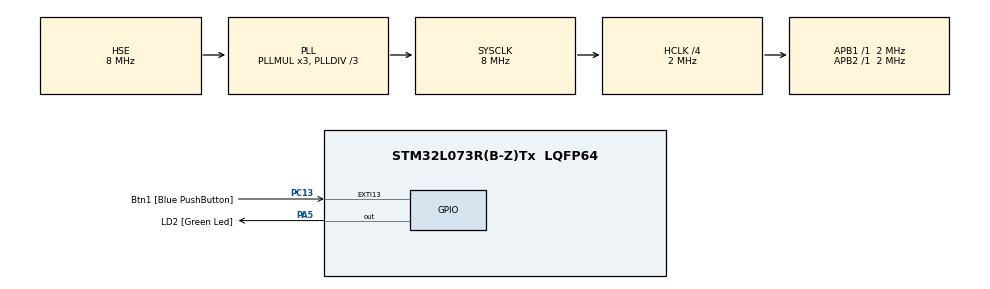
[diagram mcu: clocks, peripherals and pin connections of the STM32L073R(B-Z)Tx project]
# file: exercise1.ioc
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Mcu.Family=STM32L0
Mcu.Name=STM32L073R(B-Z)Tx
Mcu.Package=LQFP64
NVIC.EXTI4_15_IRQn=true\:0\:0\:false\:false\:true\:true
PA13.Mode=Serial_Wire
PA13.Signal=SYS_SWDIO
PA14.Mode=Serial_Wire
PA14.Signal=SYS_SWCLK
PA5.GPIO_Label=LD2 [Green Led]
PA5.Signal=GPIO_Output
PC13.GPIO_Label=Btn1 [Blue PushButton]
PC13.Signal=GPXTI13
PH0-OSC_IN.Mode=HSE-External-Oscillator
PH0-OSC_IN.Signal=RCC_OSC_IN
PH1-OSC_OUT.Mode=HSE-External-Oscillator
PH1-OSC_OUT.Signal=RCC_OSC_OUT
ProjectManager.HeapSize=0x200
ProjectManager.StackSize=0x400
ProjectManager.TargetToolchain=MDK-ARM V5
RCC.AHBCLKDivider=RCC_SYSCLK_DIV4
RCC.AHBFreq_Value=2000000
RCC.APB1Freq_Value=2000000
RCC.APB1TimFreq_Value=2000000
RCC.APB2Freq_Value=2000000
RCC.APB2TimFreq_Value=2000000
RCC.HCLKFreq_Value=2000000
RCC.HSI16_VALUE=16000000
RCC.HSI48_VALUE=48000000
RCC.HSI_VALUE=16000000
RCC.MSI_VALUE=2097000
RCC.PLLDIV=RCC_PLLDIV_3
RCC.PLLSourceVirtual=RCC_PLLSOURCE_HSE
RCC.SYSCLKFreq_VALUE=8000000
RCC.SYSCLKSource=RCC_SYSCLKSOURCE_PLLCLK
RCC.VCOOutputFreq_Value=24000000
board=NUCLEO-L073RZ

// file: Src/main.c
/**
  ******************************************************************************
  * @file           : main.c
  * @brief          : Main program body
  ******************************************************************************
  ** This notice applies to any and all portions of this file
  * that are not between comment pairs USER CODE BEGIN and
  * USER CODE END. Other portions of this file, whether
  * inserted by the user or by software development tools
  * are owned by their respective copyright owners.
  *
  * COPYRIGHT(c) 2018 STMicroelectronics
  *
  * Redistribution and use in source and binary forms, with or without modification,
  * are permitted provided that the following conditions are met:
  *   1. Redistributions of source code must retain the above copyright notice,
  *      this list of conditions and the following disclaimer.
  *   2. Redistributions in binary form must reproduce the above copyright notice,
  *      this list of conditions and the following disclaimer in the documentation
  *      and/or other materials provided with the distribution.
  *   3. Neither the name of STMicroelectronics nor the names of its contributors
  *      may be used to endorse or promote products derived from this software
  *      without specific prior written permission.
  *
  * THIS SOFTWARE IS PROVIDED BY THE COPYRIGHT HOLDERS AND CONTRIBUTORS "AS IS"
  * AND ANY EXPRESS OR IMPLIED WARRANTIES, INCLUDING, BUT NOT LIMITED TO, THE
  * IMPLIED WARRANTIES OF MERCHANTABILITY AND FITNESS FOR A PARTICULAR PURPOSE ARE
  * DISCLAIMED. IN NO EVENT SHALL THE COPYRIGHT HOLDER OR CONTRIBUTORS BE LIABLE
  * FOR ANY DIRECT, INDIRECT, INCIDENTAL, SPECIAL, EXEMPLARY, OR CONSEQUENTIAL
  * DAMAGES (INCLUDING, BUT NOT LIMITED TO, PROCUREMENT OF SUBSTITUTE GOODS OR
  * SERVICES; LOSS OF USE, DATA, OR PROFITS; OR BUSINESS INTERRUPTION) HOWEVER
  * CAUSED AND ON ANY THEORY OF LIABILITY, WHETHER IN CONTRACT, STRICT LIABILITY,
  * OR TORT (INCLUDING NEGLIGENCE OR OTHERWISE) ARISING IN ANY WAY OUT OF THE USE
  * OF THIS SOFTWARE, EVEN IF ADVISED OF THE POSSIBILITY OF SUCH DAMAGE.
  *
  ******************************************************************************
  */
#include "main.h"
#include "stm32l0xx_hal.h"

/* USER CODE BEGIN PV */
/* Private variables ---------------------------------------------------------*/
static __IO ITStatus GPIO_Btn1_Pin_Pressed = RESET;               /* Set to 1 if GPIO Btn1_Pin pressed */
int LED_pattern = 0;

/* USER CODE END PV */

void SystemClock_Config(void);
static void MX_GPIO_Init(void);

/* USER CODE BEGIN PFP */
/* Private function prototypes -----------------------------------------------*/

/* USER CODE END PFP */

int main(void)
{

  /* MCU Configuration----------------------------------------------------------*/

  /* Reset of all peripherals, Initializes the Flash interface and the Systick. */
  HAL_Init();

  /* Configure the system clock */
  SystemClock_Config();

  /* Initialize all configured peripherals */
  MX_GPIO_Init();

  /* Infinite loop */
  /* USER CODE BEGIN WHILE */
  while (1)
  {
	  if (GPIO_Btn1_Pin_Pressed == SET)
	  {
		  LED_pattern++;
		  LED_pattern %= 3;
		  switch(LED_pattern)
		  {
			  // off
			  case 0:
				  HAL_GPIO_WritePin(LD2_GPIO_Port, LD2_Pin, GPIO_PIN_RESET);
				  break;
			  // on
			  case 1:
			  // blink
			  case 2:
				  HAL_GPIO_WritePin(LD2_GPIO_Port, LD2_Pin, GPIO_PIN_SET);
			      break;
		  }
		  GPIO_Btn1_Pin_Pressed = RESET;
	  }

	  switch(LED_pattern)
	  {
		  // blink
		  case 2:
			  HAL_Delay(300);
			  HAL_GPIO_TogglePin(LD2_GPIO_Port, LD2_Pin);
		      break;
	  }

  /* USER CODE END WHILE */

  }

}

void SystemClock_Config(void)
{

  RCC_OscInitTypeDef RCC_OscInitStruct;
  RCC_ClkInitTypeDef RCC_ClkInitStruct;

    /**Configure the main internal regulator output voltage
    */
  __HAL_PWR_VOLTAGESCALING_CONFIG(PWR_REGULATOR_VOLTAGE_SCALE1);

    /**Initializes the CPU, AHB and APB busses clocks
    */
  RCC_OscInitStruct.OscillatorType = RCC_OSCILLATORTYPE_HSE;
  RCC_OscInitStruct.HSEState = RCC_HSE_ON;
  RCC_OscInitStruct.PLL.PLLState = RCC_PLL_ON;
  RCC_OscInitStruct.PLL.PLLSource = RCC_PLLSOURCE_HSE;
  RCC_OscInitStruct.PLL.PLLMUL = RCC_PLLMUL_3;
  RCC_OscInitStruct.PLL.PLLDIV = RCC_PLLDIV_3;
  if (HAL_RCC_OscConfig(&RCC_OscInitStruct) != HAL_OK)
  {
    _Error_Handler(__FILE__, __LINE__);
  }

    /**Initializes the CPU, AHB and APB busses clocks
    */
  RCC_ClkInitStruct.ClockType = RCC_CLOCKTYPE_HCLK|RCC_CLOCKTYPE_SYSCLK
                              |RCC_CLOCKTYPE_PCLK1|RCC_CLOCKTYPE_PCLK2;
  RCC_ClkInitStruct.SYSCLKSource = RCC_SYSCLKSOURCE_PLLCLK;
  RCC_ClkInitStruct.AHBCLKDivider = RCC_SYSCLK_DIV4;
  RCC_ClkInitStruct.APB1CLKDivider = RCC_HCLK_DIV1;
  RCC_ClkInitStruct.APB2CLKDivider = RCC_HCLK_DIV1;

  if (HAL_RCC_ClockConfig(&RCC_ClkInitStruct, FLASH_LATENCY_0) != HAL_OK)
  {
    _Error_Handler(__FILE__, __LINE__);
  }

    /**Configure the Systick interrupt time
    */
  HAL_SYSTICK_Config(HAL_RCC_GetHCLKFreq()/1000);

    /**Configure the Systick
    */
  HAL_SYSTICK_CLKSourceConfig(SYSTICK_CLKSOURCE_HCLK);

  /* SysTick_IRQn interrupt configuration */
  HAL_NVIC_SetPriority(SysTick_IRQn, 0, 0);
}

/** Configure pins as
        * Analog
        * Input
        * Output
        * EVENT_OUT
        * EXTI
        * Free pins are configured automatically as Analog (this feature is enabled through
        * the Code Generation settings)
*/
static void MX_GPIO_Init(void)
{

  GPIO_InitTypeDef GPIO_InitStruct;

  /* GPIO Ports Clock Enable */
  __HAL_RCC_GPIOC_CLK_ENABLE();
  __HAL_RCC_GPIOH_CLK_ENABLE();
  __HAL_RCC_GPIOA_CLK_ENABLE();
  __HAL_RCC_GPIOB_CLK_ENABLE();
  __HAL_RCC_GPIOD_CLK_ENABLE();

  /*Configure GPIO pin Output Level */
  HAL_GPIO_WritePin(LD2_GPIO_Port, LD2_Pin, GPIO_PIN_RESET);

  /*Configure GPIO pin : Btn1_Pin */
  GPIO_InitStruct.Pin = Btn1_Pin;
  GPIO_InitStruct.Mode = GPIO_MODE_IT_RISING;
  GPIO_InitStruct.Pull = GPIO_NOPULL;
  HAL_GPIO_Init(Btn1_GPIO_Port, &GPIO_InitStruct);

  /*Configure GPIO pins : PC14 PC15 PC0 PC1
                           PC2 PC3 PC4 PC5
                           PC6 PC7 PC8 PC9
                           PC10 PC11 PC12 */
  GPIO_InitStruct.Pin = GPIO_PIN_14|GPIO_PIN_15|GPIO_PIN_0|GPIO_PIN_1
                          |GPIO_PIN_2|GPIO_PIN_3|GPIO_PIN_4|GPIO_PIN_5
                          |GPIO_PIN_6|GPIO_PIN_7|GPIO_PIN_8|GPIO_PIN_9
                          |GPIO_PIN_10|GPIO_PIN_11|GPIO_PIN_12;
  GPIO_InitStruct.Mode = GPIO_MODE_ANALOG;
  GPIO_InitStruct.Pull = GPIO_NOPULL;
  HAL_GPIO_Init(GPIOC, &GPIO_InitStruct);

  /*Configure GPIO pins : PA0 PA1 PA2 PA3
                           PA4 PA6 PA7 PA8
                           PA9 PA10 PA11 PA12
                           PA15 */
  GPIO_InitStruct.Pin = GPIO_PIN_0|GPIO_PIN_1|GPIO_PIN_2|GPIO_PIN_3
                          |GPIO_PIN_4|GPIO_PIN_6|GPIO_PIN_7|GPIO_PIN_8
                          |GPIO_PIN_9|GPIO_PIN_10|GPIO_PIN_11|GPIO_PIN_12
                          |GPIO_PIN_15;
  GPIO_InitStruct.Mode = GPIO_MODE_ANALOG;
  GPIO_InitStruct.Pull = GPIO_NOPULL;
  HAL_GPIO_Init(GPIOA, &GPIO_InitStruct);

  /*Configure GPIO pin : LD2_Pin */
  GPIO_InitStruct.Pin = LD2_Pin;
  GPIO_InitStruct.Mode = GPIO_MODE_OUTPUT_PP;
  GPIO_InitStruct.Pull = GPIO_NOPULL;
  GPIO_InitStruct.Speed = GPIO_SPEED_FREQ_LOW;
  HAL_GPIO_Init(LD2_GPIO_Port, &GPIO_InitStruct);

  /*Configure GPIO pins : PB0 PB1 PB2 PB10
                           PB11 PB12 PB13 PB14
                           PB15 PB3 PB4 PB5
                           PB6 PB7 PB8 PB9 */
  GPIO_InitStruct.Pin = GPIO_PIN_0|GPIO_PIN_1|GPIO_PIN_2|GPIO_PIN_10
                          |GPIO_PIN_11|GPIO_PIN_12|GPIO_PIN_13|GPIO_PIN_14
                          |GPIO_PIN_15|GPIO_PIN_3|GPIO_PIN_4|GPIO_PIN_5
                          |GPIO_PIN_6|GPIO_PIN_7|GPIO_PIN_8|GPIO_PIN_9;
  GPIO_InitStruct.Mode = GPIO_MODE_ANALOG;
  GPIO_InitStruct.Pull = GPIO_NOPULL;
  HAL_GPIO_Init(GPIOB, &GPIO_InitStruct);

  /*Configure GPIO pin : PD2 */
  GPIO_InitStruct.Pin = GPIO_PIN_2;
  GPIO_InitStruct.Mode = GPIO_MODE_ANALOG;
  GPIO_InitStruct.Pull = GPIO_NOPULL;
  HAL_GPIO_Init(GPIOD, &GPIO_InitStruct);

  /* EXTI interrupt init*/
  HAL_NVIC_SetPriority(EXTI4_15_IRQn, 0, 0);
  HAL_NVIC_EnableIRQ(EXTI4_15_IRQn);

}

/* USER CODE BEGIN 4 */

/**
  * @brief  EXTI line detection callbacks.
  * @param  GPIO_Pin: Specifies the pins connected to the EXTI line.
  * @retval None
  */
void HAL_GPIO_EXTI_Callback(uint16_t GPIO_Pin)
{
  GPIO_Btn1_Pin_Pressed = SET;
}

/* USER CODE END 4 */

void _Error_Handler(char *file, int line)
{
  while(1)
  {
  }
}

/************************ (C) COPYRIGHT STMicroelectronics *****END OF FILE****/
